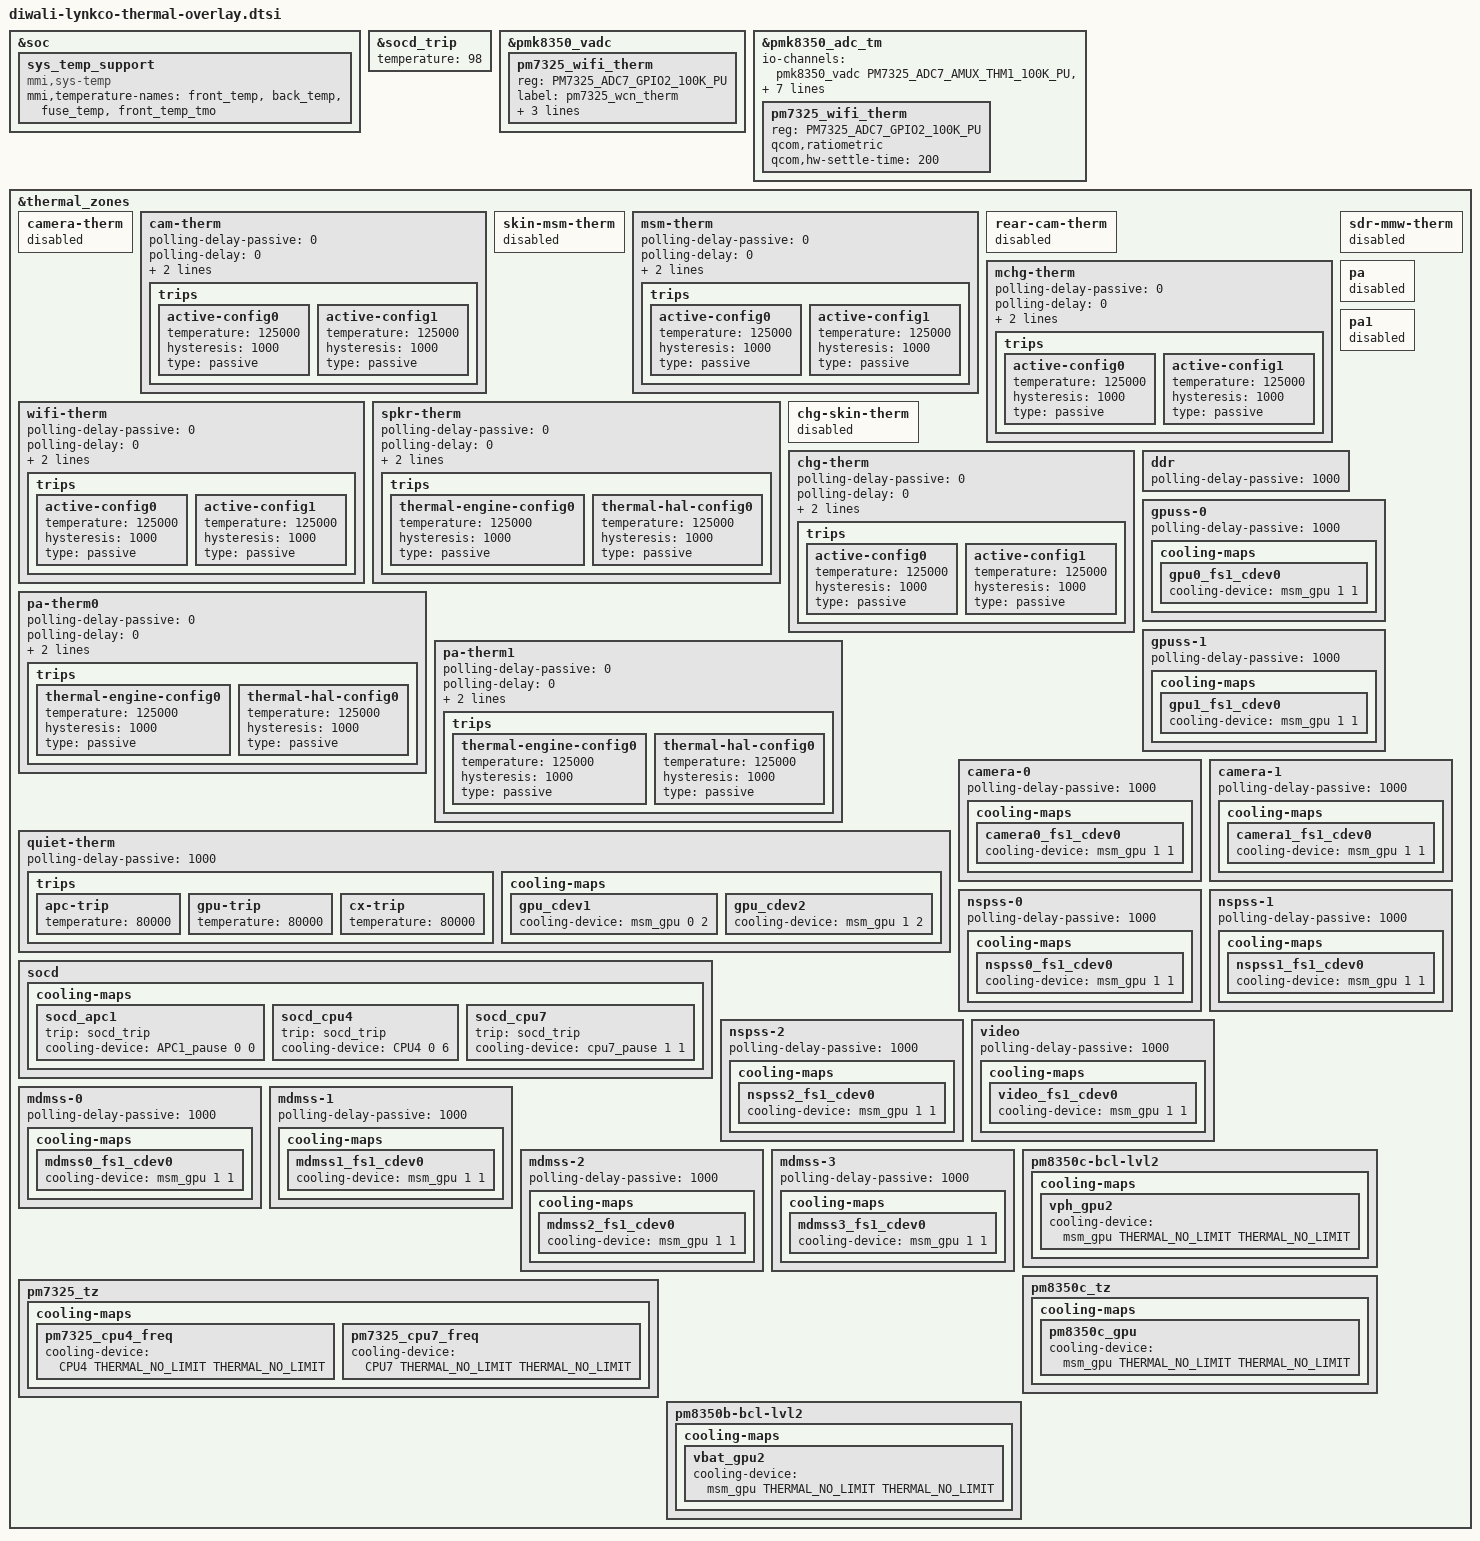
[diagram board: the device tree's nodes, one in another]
&soc {
	sys_temp_support {
		compatible = "mmi,sys-temp";
		mmi,temperature-names = "front_temp",
			"back_temp",
			"fuse_temp",
			"front_temp_tmo";
		status = "ok";
	};
};

&socd_trip {
    temperature = <98>;
};

/*
PM7325_ADC7_AMUX_THM1_100K_PU : quiet-therm (QC: defined in diwali-pmic-overlay.dtsi)
PM7325_ADC7_AMUX_THM2_100K_PU : cam-therm (QC: camera-therm)
PM7325_ADC7_AMUX_THM3_100K_PU : msm-therm (QC: skin-msm-therm)
PM7325_ADC7_AMUX_THM4_100K_PU : mchg-therm (QC: rear-cam-therm)
PM7325_ADC7_AMUX_THM5_100K_PU(PM7325_GPIO1) : pa-therm (QC: pa, define in VAdcSetting.c of modem)
PM7325_ADC7_GPIO1_100K_PU(PM7325_GPIO2): spkr-therm (QC: sdr-mmw-therm, define in VAdcSetting.c of modem)
PM7325_ADC7_GPIO2_100K_PU(PM7325_GPIO3): wifi-therm (QC: None)
PM7325_ADC7_GPIO3_100K_PU(PM7325_GPIO4): pa-therm1 (QC: pa1, define in VAdcSetting.c of modem)
PM8350B_ADC7_AMUX_THM4_100K_PU : conn-therm (QC: defined in diwali-pm8350b.dtsi)
PM8350B_ADC7_GPIO2_100K_PU: chg-therm (QC: chg-skin-therm defined in diwali-pm8350b.dtsi)
*/

&pmk8350_vadc {
	pm7325_wifi_therm {
		reg = <PM7325_ADC7_GPIO2_100K_PU>;
		label = "pm7325_wcn_therm";
		qcom,ratiometric;
		qcom,hw-settle-time = <200>;
		qcom,pre-scaling = <1 1>;
	};
};

&pmk8350_adc_tm {
	io-channels = <&pmk8350_vadc PM7325_ADC7_AMUX_THM1_100K_PU>,
			<&pmk8350_vadc PM7325_ADC7_AMUX_THM2_100K_PU>,
			<&pmk8350_vadc PM7325_ADC7_AMUX_THM3_100K_PU>,
			<&pmk8350_vadc PM7325_ADC7_AMUX_THM4_100K_PU>,
			<&pmk8350_vadc PMK8350_ADC7_AMUX_THM1_100K_PU>,
			<&pmk8350_vadc PM8350B_ADC7_AMUX_THM4_100K_PU>,
			<&pmk8350_vadc PM8350B_ADC7_GPIO2_100K_PU>,
			<&pmk8350_vadc PM7325_ADC7_GPIO2_100K_PU>;

	pm7325_wifi_therm {
		reg = <PM7325_ADC7_GPIO2_100K_PU>;
		qcom,ratiometric;
		qcom,hw-settle-time = <200>;
	};
};

&thermal_zones {
	camera-therm {
		status = "disabled";
	};
	cam-therm {
		polling-delay-passive = <0>;
		polling-delay = <0>;
		thermal-sensors = <&pmk8350_adc_tm PM7325_ADC7_AMUX_THM2_100K_PU>;
		trips {
			active-config0 {
				temperature = <125000>;
				hysteresis = <1000>;
				type = "passive";
			};

			active-config1 {
				temperature = <125000>;
				hysteresis = <1000>;
				type = "passive";
			};
		};
	};

	skin-msm-therm {
		status = "disabled";
	};
	msm-therm {
		polling-delay-passive = <0>;
		polling-delay = <0>;
		thermal-sensors = <&pmk8350_adc_tm PM7325_ADC7_AMUX_THM3_100K_PU>;
		trips {
			active-config0 {
				temperature = <125000>;
				hysteresis = <1000>;
				type = "passive";
			};

			active-config1 {
				temperature = <125000>;
				hysteresis = <1000>;
				type = "passive";
			};
		};
	};

	rear-cam-therm {
		status = "disabled";
	};
	mchg-therm {
		polling-delay-passive = <0>;
		polling-delay = <0>;
		thermal-sensors = <&pmk8350_adc_tm PM7325_ADC7_AMUX_THM4_100K_PU>;
		trips {
			active-config0 {
				temperature = <125000>;
				hysteresis = <1000>;
				type = "passive";
			};

			active-config1 {
				temperature = <125000>;
				hysteresis = <1000>;
				type = "passive";
			};
		};
	};

	wifi-therm {
		polling-delay-passive = <0>;
		polling-delay = <0>;
		thermal-sensors = <&pmk8350_adc_tm PM7325_ADC7_GPIO2_100K_PU>;
		trips {
			active-config0 {
				temperature = <125000>;
				hysteresis = <1000>;
				type = "passive";
			};

			active-config1 {
				temperature = <125000>;
				hysteresis = <1000>;
				type = "passive";
			};
		};
	};

	sdr-mmw-therm {
		status = "disabled";
	};
	spkr-therm {
		polling-delay-passive = <0>;
		polling-delay = <0>;
		thermal-sensors = <&qmi_sensor
				(QMI_MODEM_INST_ID+QMI_SDR_MMW)>;
		trips {
			thermal-engine-config0 {
				temperature = <125000>;
				hysteresis = <1000>;
				type = "passive";
			};

			thermal-hal-config0 {
				temperature = <125000>;
				hysteresis = <1000>;
				type = "passive";
			};
		};
	};

	chg-skin-therm {
		status = "disabled";
	};
	chg-therm {
		polling-delay-passive = <0>;
		polling-delay = <0>;
		thermal-sensors = <&pmk8350_adc_tm PM8350B_ADC7_GPIO2_100K_PU>;
		trips {
			active-config0 {
				temperature = <125000>;
				hysteresis = <1000>;
				type = "passive";
			};

			active-config1 {
				temperature = <125000>;
				hysteresis = <1000>;
				type = "passive";
			};
		};
	};

	pa {
		status = "disabled";
	};
	pa-therm0 {
		polling-delay-passive = <0>;
		polling-delay = <0>;
		thermal-sensors = <&qmi_sensor
				(QMI_MODEM_INST_ID+QMI_PA)>;
		trips {
			thermal-engine-config0 {
				temperature = <125000>;
				hysteresis = <1000>;
				type = "passive";
			};

			thermal-hal-config0 {
				temperature = <125000>;
				hysteresis = <1000>;
				type = "passive";
			};
		};
	};

	pa1 {
		status = "disabled";
	};
	pa-therm1 {
		polling-delay-passive = <0>;
		polling-delay = <0>;
		thermal-sensors = <&qmi_sensor
				(QMI_MODEM_INST_ID+QMI_PA_1)>;
		trips {
			thermal-engine-config0 {
				temperature = <125000>;
				hysteresis = <1000>;
				type = "passive";
			};

			thermal-hal-config0 {
				temperature = <125000>;
				hysteresis = <1000>;
				type = "passive";
			};
		};
	};

	quiet-therm {
		polling-delay-passive = <1000>;

		trips {
			apc-trip {
				temperature = <80000>;
			};
			gpu-trip {
				temperature = <80000>;
			};
			cx-trip {
				temperature = <80000>;
			};
		};
		cooling-maps {
			gpu_cdev1 {
				cooling-device = <&msm_gpu 0 2>;
			};
			gpu_cdev2 {
				cooling-device = <&msm_gpu 1 2>;
			};
		};
	};

	socd {
		cooling-maps {
			socd_apc1 {
				trip = <&socd_trip>;
				cooling-device = <&APC1_pause 0 0>;
			};
			socd_cpu4 {
				trip = <&socd_trip>;
				cooling-device = <&CPU4 0 6>;
			};
			socd_cpu7 {
				trip = <&socd_trip>;
				cooling-device = <&cpu7_pause 1 1>;
			};
		};
	};

	ddr {
		polling-delay-passive = <1000>;
	};
	gpuss-0 {
		polling-delay-passive = <1000>;
		cooling-maps {
			gpu0_fs1_cdev0 {
				cooling-device = <&msm_gpu 1 1>;
			};
		};
	};
	gpuss-1 {
		polling-delay-passive = <1000>;
		cooling-maps {
			gpu1_fs1_cdev0 {
				cooling-device = <&msm_gpu 1 1>;
			};
		};
	};
	camera-0 {
		polling-delay-passive = <1000>;
		cooling-maps {
			camera0_fs1_cdev0 {
				cooling-device = <&msm_gpu 1 1>;
			};
		};
	};
	camera-1 {
		polling-delay-passive = <1000>;
		cooling-maps {
			camera1_fs1_cdev0 {
				cooling-device = <&msm_gpu 1 1>;
			};
		};
	};
	nspss-0 {
		polling-delay-passive = <1000>;
		cooling-maps {
			nspss0_fs1_cdev0 {
				cooling-device = <&msm_gpu 1 1>;
			};
		};
	};
	nspss-1 {
		polling-delay-passive = <1000>;
		cooling-maps {
			nspss1_fs1_cdev0 {
				cooling-device = <&msm_gpu 1 1>;
			};
		};
	};
	nspss-2 {
		polling-delay-passive = <1000>;
		cooling-maps {
			nspss2_fs1_cdev0 {
				cooling-device = <&msm_gpu 1 1>;
			};
		};
	};
	video {
		polling-delay-passive = <1000>;
		cooling-maps {
			video_fs1_cdev0 {
				cooling-device = <&msm_gpu 1 1>;
			};
		};
	};
	mdmss-0 {
		polling-delay-passive = <1000>;
		cooling-maps {
			mdmss0_fs1_cdev0 {
				cooling-device = <&msm_gpu 1 1>;
			};
		};
	};
	mdmss-1 {
		polling-delay-passive = <1000>;
		cooling-maps {
			mdmss1_fs1_cdev0 {
				cooling-device = <&msm_gpu 1 1>;
			};
		};
	};
	mdmss-2 {
		polling-delay-passive = <1000>;
		cooling-maps {
			mdmss2_fs1_cdev0 {
				cooling-device = <&msm_gpu 1 1>;
			};
		};
	};
	mdmss-3 {
		polling-delay-passive = <1000>;
		cooling-maps {
			mdmss3_fs1_cdev0 {
				cooling-device = <&msm_gpu 1 1>;
			};
		};
	};

	pm7325_tz {
		cooling-maps {
			pm7325_cpu4_freq {
				cooling-device = <&CPU4 THERMAL_NO_LIMIT THERMAL_NO_LIMIT>;
			};
			pm7325_cpu7_freq {
				cooling-device = <&CPU7 THERMAL_NO_LIMIT THERMAL_NO_LIMIT>;
			};
		};
	};

	pm8350c-bcl-lvl2 {
		cooling-maps {
			vph_gpu2 {
				cooling-device = <&msm_gpu THERMAL_NO_LIMIT THERMAL_NO_LIMIT>;
			};
		};
	};
	pm8350c_tz {
		cooling-maps {
			pm8350c_gpu {
				cooling-device = <&msm_gpu THERMAL_NO_LIMIT THERMAL_NO_LIMIT>;
			};
		};
	};

	pm8350b-bcl-lvl2 {
		cooling-maps {
			vbat_gpu2 {
				cooling-device = <&msm_gpu THERMAL_NO_LIMIT THERMAL_NO_LIMIT>;
			};
		};
	};
};
